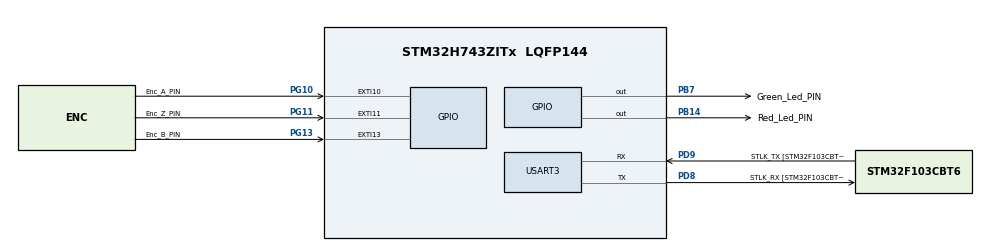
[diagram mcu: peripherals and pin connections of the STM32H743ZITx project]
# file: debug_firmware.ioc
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Mcu.Family=STM32H7
Mcu.Name=STM32H743ZITx
Mcu.Package=LQFP144
NVIC.EXTI15_10_IRQn=true\:0\:0\:false\:false\:true\:true\:true
NVIC.PriorityGroup=NVIC_PRIORITYGROUP_4
NVIC.USART3_IRQn=true\:0\:0\:false\:false\:true\:true\:true
PB14.GPIO_Label=Red_Led_PIN
PB14.Signal=GPIO_Output
PB7.GPIO_Label=Green_Led_PIN
PB7.Signal=GPIO_Output
PD8.GPIO_Label=STLK_RX [STM32F103CBT6_PA3]
PD8.Mode=Asynchronous
PD8.Signal=USART3_TX
PD9.GPIO_Label=STLK_TX [STM32F103CBT6_PA2]
PD9.Mode=Asynchronous
PD9.Signal=USART3_RX
PG10.GPIO_Label=Enc_A_PIN
PG10.Signal=GPXTI10
PG11.GPIO_Label=Enc_Z_PIN
PG11.Signal=GPXTI11
PG13.GPIO_Label=Enc_B_PIN
PG13.Signal=GPXTI13
ProjectManager.HeapSize=0x200
ProjectManager.StackSize=0x400
ProjectManager.TargetToolchain=STM32CubeIDE
RCC.48MHZClocksFreq_Value=24000000
RCC.ADCFreq_Value=129000000
RCC.AHBFreq_Value=216000000
RCC.APB1CLKDivider=RCC_HCLK_DIV4
RCC.APB1Freq_Value=120000000
RCC.APB1TimFreq_Value=108000000
RCC.APB2CLKDivider=RCC_HCLK_DIV2
RCC.APB2Freq_Value=120000000
RCC.APB2TimFreq_Value=216000000
RCC.APB3Freq_Value=120000000
RCC.APB4Freq_Value=120000000
RCC.CortexFreq_Value=480000000
RCC.D1PPRE=RCC_APB3_DIV2
RCC.D2PPRE1=RCC_APB1_DIV2
RCC.D2PPRE2=RCC_APB2_DIV2
RCC.D3PPRE=RCC_APB4_DIV2
RCC.DIVM1=4
RCC.DIVN1=60
RCC.DIVQ1=4
RCC.HCLKFreq_Value=240000000
RCC.HPRE=RCC_HCLK_DIV2
RCC.HSE_VALUE=8000000
RCC.HSI_VALUE=64000000
RCC.PLL2FRACN=0
RCC.PLL3FRACN=0
RCC.PLLFRACN=0
RCC.PLLM=25
RCC.PLLMUL=RCC_PLL_MUL9
RCC.PLLN=432
RCC.PLLQ=9
RCC.PRESCALERUSB=RCC_USBCLKSOURCE_PLL_DIV1_5
RCC.PWR_Regulator_Voltage_Scale=PWR_REGULATOR_VOLTAGE_SCALE0
RCC.SYSCLKFreq_VALUE=480000000
RCC.SYSCLKSource=RCC_SYSCLKSOURCE_PLLCLK
RCC.SYSCLKSourceVirtual=RCC_SYSCLKSOURCE_PLLCLK
RCC.USBFreq_Value=240000000
RCC.VCOOutputFreq_Value=432000000
USART3.VirtualMode-Asynchronous=VM_ASYNC
board=NUCLEO-H743ZI

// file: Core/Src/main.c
/* USER CODE BEGIN Header */
/**
  ******************************************************************************
  * @file           : main.c
  * @brief          : Main program body
  ******************************************************************************
  * @attention
  *
  * <h2><center>&copy; Copyright (c) 2021 STMicroelectronics.
  * All rights reserved.</center></h2>
  *
  * This software component is licensed by ST under BSD 3-Clause license,
  * the "License"; You may not use this file except in compliance with the
  * License. You may obtain a copy of the License at:
  *                        opensource.org/licenses/BSD-3-Clause
  *
  ******************************************************************************
  */
/* USER CODE END Header */
#include "main.h"
#include "usart.h"
#include "gpio.h"

/* USER CODE BEGIN Includes */
#include "Encoder_3C.h"
/* USER CODE END Includes */

/* USER CODE BEGIN PV */
enc3c_t pulley_enc;
uint8_t i;
/* USER CODE END PV */

void SystemClock_Config(void);

int main(void)
{

  /* MCU Configuration--------------------------------------------------------*/

  /* Reset of all peripherals, Initializes the Flash interface and the Systick. */
  HAL_Init();

  /* Configure the system clock */
  SystemClock_Config();

  /* Initialize all configured peripherals */
  MX_GPIO_Init();
  MX_USART3_UART_Init();
  /* USER CODE BEGIN 2 */
  encoder_init(&pulley_enc, Enc_A_PIN_GPIO_Port, Enc_A_PIN_Pin, Enc_B_PIN_GPIO_Port, Enc_B_PIN_Pin,
  				  Enc_Z_PIN_GPIO_Port, Enc_Z_PIN_Pin, ENC3_FORWARD, 5000);
  i=0;
  /* USER CODE END 2 */

  /* Infinite loop */
  while (1)
  {
	  i=i+1;
  }
}

void SystemClock_Config(void)
{
  RCC_OscInitTypeDef RCC_OscInitStruct = {0};
  RCC_ClkInitTypeDef RCC_ClkInitStruct = {0};
  RCC_PeriphCLKInitTypeDef PeriphClkInitStruct = {0};

  /** Supply configuration update enable
  */
  HAL_PWREx_ConfigSupply(PWR_LDO_SUPPLY);
  /** Configure the main internal regulator output voltage
  */
  __HAL_PWR_VOLTAGESCALING_CONFIG(PWR_REGULATOR_VOLTAGE_SCALE0);

  while(!__HAL_PWR_GET_FLAG(PWR_FLAG_VOSRDY)) {}
  /** Initializes the RCC Oscillators according to the specified parameters
  * in the RCC_OscInitTypeDef structure.
  */
  RCC_OscInitStruct.OscillatorType = RCC_OSCILLATORTYPE_HSI;
  RCC_OscInitStruct.HSIState = RCC_HSI_DIV1;
  RCC_OscInitStruct.HSICalibrationValue = RCC_HSICALIBRATION_DEFAULT;
  RCC_OscInitStruct.PLL.PLLState = RCC_PLL_ON;
  RCC_OscInitStruct.PLL.PLLSource = RCC_PLLSOURCE_HSI;
  RCC_OscInitStruct.PLL.PLLM = 4;
  RCC_OscInitStruct.PLL.PLLN = 60;
  RCC_OscInitStruct.PLL.PLLP = 2;
  RCC_OscInitStruct.PLL.PLLQ = 4;
  RCC_OscInitStruct.PLL.PLLR = 2;
  RCC_OscInitStruct.PLL.PLLRGE = RCC_PLL1VCIRANGE_3;
  RCC_OscInitStruct.PLL.PLLVCOSEL = RCC_PLL1VCOWIDE;
  RCC_OscInitStruct.PLL.PLLFRACN = 0;
  if (HAL_RCC_OscConfig(&RCC_OscInitStruct) != HAL_OK)
  {
    Error_Handler();
  }
  /** Initializes the CPU, AHB and APB buses clocks
  */
  RCC_ClkInitStruct.ClockType = RCC_CLOCKTYPE_HCLK|RCC_CLOCKTYPE_SYSCLK
                              |RCC_CLOCKTYPE_PCLK1|RCC_CLOCKTYPE_PCLK2
                              |RCC_CLOCKTYPE_D3PCLK1|RCC_CLOCKTYPE_D1PCLK1;
  RCC_ClkInitStruct.SYSCLKSource = RCC_SYSCLKSOURCE_PLLCLK;
  RCC_ClkInitStruct.SYSCLKDivider = RCC_SYSCLK_DIV1;
  RCC_ClkInitStruct.AHBCLKDivider = RCC_HCLK_DIV2;
  RCC_ClkInitStruct.APB3CLKDivider = RCC_APB3_DIV2;
  RCC_ClkInitStruct.APB1CLKDivider = RCC_APB1_DIV2;
  RCC_ClkInitStruct.APB2CLKDivider = RCC_APB2_DIV2;
  RCC_ClkInitStruct.APB4CLKDivider = RCC_APB4_DIV2;

  if (HAL_RCC_ClockConfig(&RCC_ClkInitStruct, FLASH_LATENCY_4) != HAL_OK)
  {
    Error_Handler();
  }
  PeriphClkInitStruct.PeriphClockSelection = RCC_PERIPHCLK_USART3;
  PeriphClkInitStruct.Usart234578ClockSelection = RCC_USART234578CLKSOURCE_D2PCLK1;
  if (HAL_RCCEx_PeriphCLKConfig(&PeriphClkInitStruct) != HAL_OK)
  {
    Error_Handler();
  }
}

void Error_Handler(void)
{
  __disable_irq();
  while (1)
  {
  }
}

/************************ (C) COPYRIGHT STMicroelectronics *****END OF FILE****/
